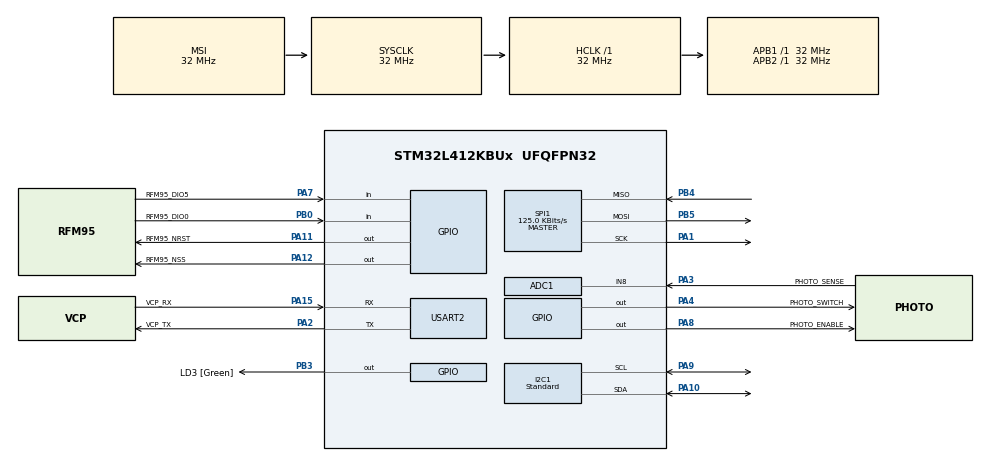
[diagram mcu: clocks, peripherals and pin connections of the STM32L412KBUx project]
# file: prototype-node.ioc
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Mcu.Family=STM32L4
RCC.CortexFreq_Value=32000000
I2C1.I2C_Speed_Mode=I2C_Standard
SPI1.VirtualType=VM_MASTER
NVIC.RTC_WKUP_IRQn=true\:0\:0\:false\:false\:true\:true\:true
VP_RTC_VS_RTC_Activate.Mode=RTC_Enabled
PB0.GPIO_Label=RFM95_DIO0
PA15\ (JTDI).Signal=USART2_RX
PC15-OSC32_OUT\ (PC15).Mode=LSE-External-Oscillator
ProjectManager.StackSize=0x400
PC14-OSC32_IN\ (PC14).Mode=LSE-External-Oscillator
PA15\ (JTDI).Mode=Asynchronous
PA14\ (JTCK/SWCLK).Signal=SYS_JTCK-SWCLK
PA12.Signal=GPIO_Output
SPI1.Direction=SPI_DIRECTION_2LINES
RCC.HCLKFreq_Value=32000000
RCC.FLatency=FLASH_LATENCY_1
ADC1.Resolution=ADC_RESOLUTION_12B
RCC.APB2TimFreq_Value=32000000
SPI1.CalculateBaudRate=125.0 KBits/s
RCC.HSICalibrationValue=16
PA1.GPIO_PuPd=GPIO_NOPULL
RCC.AHBFreq_Value=32000000
PA12.PinState=GPIO_PIN_SET
ADC1.Channel-0\#ChannelRegularConversion=ADC_CHANNEL_8
RCC.HSE_VALUE=8000000
USART2.VirtualMode-Asynchronous=VM_ASYNC
PA0-CK_IN.Signal=RCC_CK_IN
PA13\ (JTMS/SWDIO).GPIO_Label=SWDIO
RCC.LSE_Drive_Capability=RCC_LSEDRIVE_LOW
PB5.Mode=Full_Duplex_Master
SPI1.DataSize=SPI_DATASIZE_8BIT
SH.ADCx_IN8.0=ADC1_IN8,IN8-Single-Ended
PA8.Signal=GPIO_Output
PA14\ (JTCK/SWCLK).Mode=Serial_Wire
ADC1.SamplingTime-0\#ChannelRegularConversion=ADC_SAMPLETIME_2CYCLES_5
Mcu.Package=UFQFPN32
ADC1.OversamplingMode=DISABLE
PA2.GPIO_Label=VCP_TX
PA10.Signal=I2C1_SDA
PA14\ (JTCK/SWCLK).GPIO_Label=SWCLK
RCC.APB1TimFreq_Value=32000000
SPI1.BaudRatePrescaler=SPI_BAUDRATEPRESCALER_256
PA4.GPIO_Label=PHOTO_SWITCH
RCC.MSIClockRange=RCC_MSIRANGE_10
RCC.HSI48_VALUE=48000000
PA3.Signal=ADCx_IN8
PB3\ (JTDO/TRACESWO).GPIO_Label=LD3 [Green]
RCC.MSI_VALUE=32000000
ADC1.Rank-0\#ChannelRegularConversion=1
RTC.WakeUpCounter=0
PA13\ (JTMS/SWDIO).Mode=Serial_Wire
PA10.Mode=I2C
RTC.WakeUpClock=RTC_WAKEUPCLOCK_CK_SPRE_16BITS
PA0-CK_IN.Mode=HSE-External-Clock-Source-for-LittleOrca
ADC1.OffsetNumber-0\#ChannelRegularConversion=ADC_OFFSET_NONE
PA11.GPIO_Label=RFM95_NRST
PC15-OSC32_OUT\ (PC15).Signal=RCC_OSC32_OUT
PA12.GPIO_Label=RFM95_NSS
PA9.Mode=I2C
PA8.GPIO_Label=PHOTO_ENABLE
PB3\ (JTDO/TRACESWO).Signal=GPIO_Output
ProjectManager.TargetToolchain=STM32CubeIDE
PA9.Signal=I2C1_SCL
I2C1.Timing=0x00707CBB
RCC.USBFreq_Value=32000000
PA7.GPIO_PuPd=GPIO_PULLUP
PA1.Signal=SPI1_SCK
board=NUCLEO-L412KB
RCC.VCOOutputFreq_Value=256000000
RCC.APB2Freq_Value=32000000
PA1.Mode=Full_Duplex_Master
SPI1.Mode=SPI_MODE_MASTER
RCC.ADCFreq_Value=32000000
PB4\ (NJTRST).Mode=Full_Duplex_Master
ADC1.NbrOfConversion=1
PA15\ (JTDI).GPIO_Label=VCP_RX
Mcu.Name=STM32L412KBUx
SPI1.NSSPMode=SPI_NSS_PULSE_DISABLE
PA2.Signal=USART2_TX
PA4.Signal=GPIO_Output
RCC.SYSCLKFreq_VALUE=32000000
PB5.Signal=SPI1_MOSI
PA7.GPIO_Label=RFM95_DIO5
ADC1.master=1
PC14-OSC32_IN\ (PC14).Signal=RCC_OSC32_IN
PB5.GPIO_PuPd=GPIO_NOPULL
PA11.Signal=GPIO_Output
ProjectManager.HeapSize=0x200
RCC.HSI_VALUE=16000000
VP_RTC_VS_RTC_WakeUp_intern.Mode=WakeUp
NVIC.PriorityGroup=NVIC_PRIORITYGROUP_4
ADC1.NbrOfConversionFlag=1
PA2.Mode=Asynchronous
PA11.PinState=GPIO_PIN_RESET
RCC.APB1Freq_Value=32000000
PB0.Signal=GPIO_Input
PB4\ (NJTRST).GPIO_PuPd=GPIO_NOPULL
PB0.GPIO_PuPd=GPIO_PULLUP
PA13\ (JTMS/SWDIO).Signal=SYS_JTMS-SWDIO
PA3.GPIO_Label=PHOTO_SENSE
PA7.Signal=GPIO_Input
PB4\ (NJTRST).Signal=SPI1_MISO

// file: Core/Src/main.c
/* USER CODE BEGIN Header */
/**
  ******************************************************************************
  * @file           : main.c
  * @brief          : Main program body
  ******************************************************************************
  * @attention
  *
  * <h2><center>&copy; Copyright (c) 2020 STMicroelectronics.
  * All rights reserved.</center></h2>
  *
  * This software component is licensed by ST under BSD 3-Clause license,
  * the "License"; You may not use this file except in compliance with the
  * License. You may obtain a copy of the License at:
  *                        opensource.org/licenses/BSD-3-Clause
  *
  ******************************************************************************
  */
/* USER CODE END Header */
#include "main.h"
#include "adc.h"
#include "i2c.h"
#include "rtc.h"
#include "spi.h"
#include "usart.h"
#include "gpio.h"

/* USER CODE BEGIN Includes */
#include "application.h"
/* USER CODE END Includes */

void SystemClock_Config(void);

int main(void)
{

  /* MCU Configuration--------------------------------------------------------*/

  /* Reset of all peripherals, Initializes the Flash interface and the Systick. */
  HAL_Init();

  /* Configure the system clock */
  SystemClock_Config();

  /* USER CODE BEGIN SysInit
  // Check and handle if the system was resumed from StandBy mode */
  if(__HAL_PWR_GET_FLAG(PWR_FLAG_SB) != RESET)
  {
	// Clear Standby flag
	__HAL_PWR_CLEAR_FLAG(PWR_FLAG_SB);
  }
  /* USER CODE END SysInit */

  /* Initialize all configured peripherals */
  MX_GPIO_Init();
  MX_USART2_UART_Init();
  MX_I2C1_Init();
  MX_SPI1_Init();
  MX_ADC1_Init();
  MX_RTC_Init();
  /* USER CODE BEGIN 2 */
  application_main();

  // TODO: Enable ultra low power BOR and PVD supply monitoring?
  HAL_PWREx_EnableBORPVD_ULP();

  // Disable all used wakeup sources
  HAL_RTCEx_DeactivateWakeUpTimer(&hrtc);

  // Clear all related wakeup flags
  __HAL_PWR_CLEAR_FLAG(PWR_FLAG_WU);

  // Setting the Wake up time 1s * 0x0E10 = 1h
  // 10min = 0x0258
  // 10 sec = 0x000a
  HAL_RTCEx_SetWakeUpTimer_IT(&hrtc, 0x0258, RTC_WAKEUPCLOCK_CK_SPRE_16BITS, 0);

  // Enter the Standby mode
  HAL_PWR_EnterSTANDBYMode();

  /* USER CODE END 2 */

  /* Infinite loop */
  while (1)
  {

  }
}

void SystemClock_Config(void)
{
  RCC_OscInitTypeDef RCC_OscInitStruct = {0};
  RCC_ClkInitTypeDef RCC_ClkInitStruct = {0};
  RCC_PeriphCLKInitTypeDef PeriphClkInit = {0};

  /** Configure LSE Drive Capability
  */
  HAL_PWR_EnableBkUpAccess();
  __HAL_RCC_LSEDRIVE_CONFIG(RCC_LSEDRIVE_LOW);
  /** Configure the main internal regulator output voltage
  */
  if (HAL_PWREx_ControlVoltageScaling(PWR_REGULATOR_VOLTAGE_SCALE1) != HAL_OK)
  {
    Error_Handler();
  }
  /** Initializes the RCC Oscillators according to the specified parameters
  * in the RCC_OscInitTypeDef structure.
  */
  RCC_OscInitStruct.OscillatorType = RCC_OSCILLATORTYPE_LSI|RCC_OSCILLATORTYPE_LSE
                              |RCC_OSCILLATORTYPE_MSI;
  RCC_OscInitStruct.LSEState = RCC_LSE_ON;
  RCC_OscInitStruct.LSIState = RCC_LSI_ON;
  RCC_OscInitStruct.MSIState = RCC_MSI_ON;
  RCC_OscInitStruct.MSICalibrationValue = 0;
  RCC_OscInitStruct.MSIClockRange = RCC_MSIRANGE_10;
  RCC_OscInitStruct.PLL.PLLState = RCC_PLL_NONE;
  if (HAL_RCC_OscConfig(&RCC_OscInitStruct) != HAL_OK)
  {
    Error_Handler();
  }
  /** Initializes the CPU, AHB and APB buses clocks
  */
  RCC_ClkInitStruct.ClockType = RCC_CLOCKTYPE_HCLK|RCC_CLOCKTYPE_SYSCLK
                              |RCC_CLOCKTYPE_PCLK1|RCC_CLOCKTYPE_PCLK2;
  RCC_ClkInitStruct.SYSCLKSource = RCC_SYSCLKSOURCE_MSI;
  RCC_ClkInitStruct.AHBCLKDivider = RCC_SYSCLK_DIV1;
  RCC_ClkInitStruct.APB1CLKDivider = RCC_HCLK_DIV1;
  RCC_ClkInitStruct.APB2CLKDivider = RCC_HCLK_DIV1;

  if (HAL_RCC_ClockConfig(&RCC_ClkInitStruct, FLASH_LATENCY_1) != HAL_OK)
  {
    Error_Handler();
  }
  PeriphClkInit.PeriphClockSelection = RCC_PERIPHCLK_RTC|RCC_PERIPHCLK_USART2
                              |RCC_PERIPHCLK_I2C1|RCC_PERIPHCLK_ADC;
  PeriphClkInit.Usart2ClockSelection = RCC_USART2CLKSOURCE_PCLK1;
  PeriphClkInit.I2c1ClockSelection = RCC_I2C1CLKSOURCE_PCLK1;
  PeriphClkInit.RTCClockSelection = RCC_RTCCLKSOURCE_LSI;
  if (HAL_RCCEx_PeriphCLKConfig(&PeriphClkInit) != HAL_OK)
  {
    Error_Handler();
  }
  /** Enable MSI Auto calibration
  */
  HAL_RCCEx_EnableMSIPLLMode();
}

void Error_Handler(void)
{
}

/************************ (C) COPYRIGHT STMicroelectronics *****END OF FILE****/
